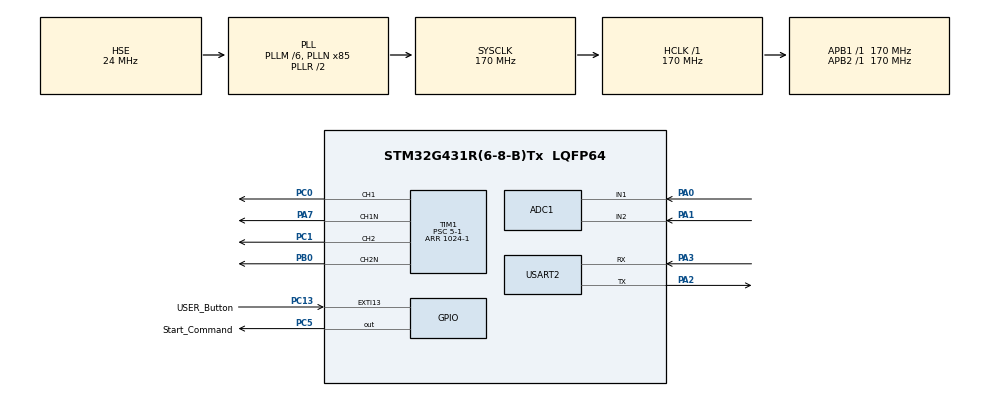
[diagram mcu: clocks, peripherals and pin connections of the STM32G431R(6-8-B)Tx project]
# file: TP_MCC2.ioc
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ADC1.Channel-0\#ChannelRegularConversion=ADC_CHANNEL_1
ADC1.Channel-1\#ChannelRegularConversion=ADC_CHANNEL_2
ADC1.DMAContinuousRequests=ENABLE
ADC1.EOCSelection=ADC_EOC_SEQ_CONV
ADC1.ExternalTrigConv=ADC_EXTERNALTRIG_T1_CC3
ADC1.NbrOfConversion=2
ADC1.NbrOfConversionFlag=1
ADC1.OffsetNumber-0\#ChannelRegularConversion=ADC_OFFSET_NONE
ADC1.OffsetNumber-1\#ChannelRegularConversion=ADC_OFFSET_NONE
ADC1.Rank-0\#ChannelRegularConversion=1
ADC1.Rank-1\#ChannelRegularConversion=2
ADC1.SamplingTime-0\#ChannelRegularConversion=ADC_SAMPLETIME_12CYCLES_5
ADC1.SamplingTime-1\#ChannelRegularConversion=ADC_SAMPLETIME_12CYCLES_5
ADC1.master=1
Dma.ADC1.0.Direction=DMA_PERIPH_TO_MEMORY
Dma.ADC1.0.EventEnable=DISABLE
Dma.ADC1.0.Instance=DMA1_Channel1
Dma.ADC1.0.MemDataAlignment=DMA_MDATAALIGN_HALFWORD
Dma.ADC1.0.MemInc=DMA_MINC_ENABLE
Dma.ADC1.0.Mode=DMA_CIRCULAR
Dma.ADC1.0.PeriphDataAlignment=DMA_PDATAALIGN_HALFWORD
Dma.ADC1.0.PeriphInc=DMA_PINC_DISABLE
Dma.ADC1.0.Polarity=HAL_DMAMUX_REQ_GEN_RISING
Dma.ADC1.0.Priority=DMA_PRIORITY_LOW
Dma.ADC1.0.RequestNumber=1
Dma.ADC1.0.SignalID=NONE
Dma.ADC1.0.SyncEnable=DISABLE
Dma.ADC1.0.SyncPolarity=HAL_DMAMUX_SYNC_NO_EVENT
Dma.ADC1.0.SyncRequestNumber=1
Dma.ADC1.0.SyncSignalID=NONE
Dma.Request0=ADC1
Mcu.Family=STM32G4
Mcu.Name=STM32G431R(6-8-B)Tx
Mcu.Package=LQFP64
NVIC.DMA1_Channel1_IRQn=true\:0\:0\:false\:false\:true\:false\:true
NVIC.EXTI15_10_IRQn=true\:0\:0\:false\:false\:true\:true\:true
NVIC.PriorityGroup=NVIC_PRIORITYGROUP_4
NVIC.TIM6_DAC_IRQn=true\:0\:0\:false\:false\:true\:true\:true
NVIC.USART2_IRQn=true\:0\:0\:false\:false\:true\:true\:true
PA0.Mode=IN1-Single-Ended
PA0.Signal=ADC1_IN1
PA1.Mode=IN2-Single-Ended
PA1.Signal=ADC1_IN2
PA13.Mode=Serial_Wire
PA13.Signal=SYS_JTMS-SWDIO
PA14.Mode=Serial_Wire
PA14.Signal=SYS_JTCK-SWCLK
PA2.Mode=Asynchronous
PA2.Signal=USART2_TX
PA3.Mode=Asynchronous
PA3.Signal=USART2_RX
PA7.Mode=PWM Generation1 CH1 CH1N
PA7.Signal=TIM1_CH1N
PB0.Mode=PWM Generation2 CH2 CH2N
PB0.Signal=TIM1_CH2N
PC0.Signal=S_TIM1_CH1
PC1.Signal=S_TIM1_CH2
PC13.GPIO_Label=USER_Button
PC13.GPIO_ModeDefaultEXTI=GPIO_MODE_IT_FALLING
PC13.Signal=GPXTI13
PC5.GPIO_Label=Start_Command
PC5.Signal=GPIO_Output
PF0-OSC_IN.Mode=HSE-External-Oscillator
PF0-OSC_IN.Signal=RCC_OSC_IN
PF1-OSC_OUT.Mode=HSE-External-Oscillator
PF1-OSC_OUT.Signal=RCC_OSC_OUT
ProjectManager.HeapSize=0x200
ProjectManager.StackSize=0x400
ProjectManager.TargetToolchain=STM32CubeIDE
RCC.ADC12Freq_Value=170000000
RCC.AHBFreq_Value=170000000
RCC.APB1Freq_Value=170000000
RCC.APB1TimFreq_Value=170000000
RCC.APB2Freq_Value=170000000
RCC.APB2TimFreq_Value=170000000
RCC.CortexFreq_Value=170000000
RCC.EXTERNAL_CLOCK_VALUE=12288000
RCC.HCLKFreq_Value=170000000
RCC.HSE_VALUE=24000000
RCC.HSI48_VALUE=48000000
RCC.HSI_VALUE=16000000
RCC.LSE_VALUE=32768
RCC.PLLM=RCC_PLLM_DIV6
RCC.PLLN=85
RCC.PLLSourceVirtual=RCC_PLLSOURCE_HSE
RCC.RTCClockSelection=RCC_RTCCLKSOURCE_LSE
RCC.SYSCLKFreq_VALUE=170000000
RCC.SYSCLKSource=RCC_SYSCLKSOURCE_PLLCLK
RCC.USBFreq_Value=170000000
RCC.VCOOutputFreq_Value=340000000
SH.S_TIM1_CH1.0=TIM1_CH1,PWM Generation1 CH1 CH1N
SH.S_TIM1_CH2.0=TIM1_CH2,PWM Generation2 CH2 CH2N
TIM1.Channel-Output\ Compare3\ No\ Output=TIM_CHANNEL_3
TIM1.Channel-PWM\ Generation1\ CH1\ CH1N=TIM_CHANNEL_1
TIM1.Channel-PWM\ Generation2\ CH2\ CH2N=TIM_CHANNEL_2
TIM1.CounterMode=TIM_COUNTERMODE_CENTERALIGNED1
TIM1.DeadTime=202
TIM1.DeadTimePreload=ENABLE
TIM1.OCMode_3=TIM_OCMODE_PULSE_ON_COMPARE
TIM1.PeriodNoDither=1024-1
TIM1.Prescaler=5-1
TIM1.PulseNoDither_1=533
TIM1.PulseNoDither_2=533
TIM1.TIM_MasterOutputTrigger=TIM_TRGO_OC3REF
TIM6.AutoReloadPreload=TIM_AUTORELOAD_PRELOAD_DISABLE
TIM6.PeriodNoDither=2594-1
TIM6.Prescaler=65536-1
USART2.VirtualMode-Asynchronous=VM_ASYNC
VP_SYS_VS_DBSignals.Mode=DisableDeadBatterySignals
VP_TIM1_VS_ClockSourceINT.Mode=Internal
VP_TIM1_VS_no_output3.Mode=Output Compare3 No Output
VP_TIM6_VS_ClockSourceINT.Mode=Enable_Timer
board=NUCLEO-G431RB

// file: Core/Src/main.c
/* USER CODE BEGIN Header */
/**
  ******************************************************************************
  * @file           : main.c
  * @brief          : Main program body
  ******************************************************************************
  * @attention
  *
  * <h2><center>&copy; Copyright (c) 2021 STMicroelectronics.
  * All rights reserved.</center></h2>
  *
  * This software component is licensed by ST under BSD 3-Clause license,
  * the "License"; You may not use this file except in compliance with the
  * License. You may obtain a copy of the License at:
  *                        opensource.org/licenses/BSD-3-Clause
  *
  ******************************************************************************
  */
/* USER CODE END Header */
#include "main.h"

ADC_HandleTypeDef hadc1;
DMA_HandleTypeDef hdma_adc1;

TIM_HandleTypeDef htim1;
TIM_HandleTypeDef htim6;

UART_HandleTypeDef huart2;

/* USER CODE BEGIN PV */
uint16_t pData[2];// Buffer for the DMA to fill
char uart_rx_buffer[32];// Buffer for the UART to fill

/* USER CODE END PV */

void SystemClock_Config(void);
static void MX_GPIO_Init(void);
static void MX_USART2_UART_Init(void);
static void MX_TIM1_Init(void);
static void MX_DMA_Init(void);
static void MX_ADC1_Init(void);
static void MX_TIM6_Init(void);

int main(void)
{

  /* MCU Configuration--------------------------------------------------------*/

  /* Reset of all peripherals, Initializes the Flash interface and the Systick. */
  HAL_Init();

  /* Configure the system clock */
  SystemClock_Config();

  /* Initialize all configured peripherals */
  MX_GPIO_Init();
  MX_USART2_UART_Init();
  MX_TIM1_Init();
  MX_DMA_Init();
  MX_ADC1_Init();
  MX_TIM6_Init();
  /* USER CODE BEGIN 2 */
  shell_init();// Initialisation of the shell
  HAL_ADCEx_Calibration_Start(&hadc1, ADC_SINGLE_ENDED);// Calibration of the ADC
  HAL_ADC_Start_DMA(&hadc1, (uint32_t*) pData, 2);// Starting the DMA
  HAL_TIM_Base_Start_IT(&htim6);// Starting the Timer 6
  HAL_TIM_Base_Start(&htim1);// Starting the Timer 1

  /* USER CODE END 2 */

  /* Infinite loop */
  /* USER CODE BEGIN WHILE */
  while (1)
  {
	  shellTreatment();
    /* USER CODE END WHILE */

  }
}

void SystemClock_Config(void)
{
  RCC_OscInitTypeDef RCC_OscInitStruct = {0};
  RCC_ClkInitTypeDef RCC_ClkInitStruct = {0};
  RCC_PeriphCLKInitTypeDef PeriphClkInit = {0};

  /** Configure the main internal regulator output voltage
  */
  HAL_PWREx_ControlVoltageScaling(PWR_REGULATOR_VOLTAGE_SCALE1_BOOST);
  /** Initializes the RCC Oscillators according to the specified parameters
  * in the RCC_OscInitTypeDef structure.
  */
  RCC_OscInitStruct.OscillatorType = RCC_OSCILLATORTYPE_HSE;
  RCC_OscInitStruct.HSEState = RCC_HSE_ON;
  RCC_OscInitStruct.PLL.PLLState = RCC_PLL_ON;
  RCC_OscInitStruct.PLL.PLLSource = RCC_PLLSOURCE_HSE;
  RCC_OscInitStruct.PLL.PLLM = RCC_PLLM_DIV6;
  RCC_OscInitStruct.PLL.PLLN = 85;
  RCC_OscInitStruct.PLL.PLLP = RCC_PLLP_DIV2;
  RCC_OscInitStruct.PLL.PLLQ = RCC_PLLQ_DIV2;
  RCC_OscInitStruct.PLL.PLLR = RCC_PLLR_DIV2;
  if (HAL_RCC_OscConfig(&RCC_OscInitStruct) != HAL_OK)
  {
    Error_Handler();
  }
  /** Initializes the CPU, AHB and APB buses clocks
  */
  RCC_ClkInitStruct.ClockType = RCC_CLOCKTYPE_HCLK|RCC_CLOCKTYPE_SYSCLK
                              |RCC_CLOCKTYPE_PCLK1|RCC_CLOCKTYPE_PCLK2;
  RCC_ClkInitStruct.SYSCLKSource = RCC_SYSCLKSOURCE_PLLCLK;
  RCC_ClkInitStruct.AHBCLKDivider = RCC_SYSCLK_DIV1;
  RCC_ClkInitStruct.APB1CLKDivider = RCC_HCLK_DIV1;
  RCC_ClkInitStruct.APB2CLKDivider = RCC_HCLK_DIV1;

  if (HAL_RCC_ClockConfig(&RCC_ClkInitStruct, FLASH_LATENCY_4) != HAL_OK)
  {
    Error_Handler();
  }
  /** Initializes the peripherals clocks
  */
  PeriphClkInit.PeriphClockSelection = RCC_PERIPHCLK_USART2|RCC_PERIPHCLK_ADC12;
  PeriphClkInit.Usart2ClockSelection = RCC_USART2CLKSOURCE_PCLK1;
  PeriphClkInit.Adc12ClockSelection = RCC_ADC12CLKSOURCE_SYSCLK;
  if (HAL_RCCEx_PeriphCLKConfig(&PeriphClkInit) != HAL_OK)
  {
    Error_Handler();
  }
}

static void MX_ADC1_Init(void)
{

  ADC_MultiModeTypeDef multimode = {0};
  ADC_ChannelConfTypeDef sConfig = {0};

  /** Common config
  */
  hadc1.Instance = ADC1;
  hadc1.Init.ClockPrescaler = ADC_CLOCK_SYNC_PCLK_DIV4;
  hadc1.Init.Resolution = ADC_RESOLUTION_12B;
  hadc1.Init.DataAlign = ADC_DATAALIGN_RIGHT;
  hadc1.Init.GainCompensation = 0;
  hadc1.Init.ScanConvMode = ADC_SCAN_DISABLE;
  hadc1.Init.EOCSelection = ADC_EOC_SEQ_CONV;
  hadc1.Init.LowPowerAutoWait = DISABLE;
  hadc1.Init.ContinuousConvMode = DISABLE;
  hadc1.Init.NbrOfConversion = 1;
  hadc1.Init.DiscontinuousConvMode = DISABLE;
  hadc1.Init.ExternalTrigConv = ADC_EXTERNALTRIG_T1_CC3;
  hadc1.Init.ExternalTrigConvEdge = ADC_EXTERNALTRIGCONVEDGE_RISING;
  hadc1.Init.DMAContinuousRequests = ENABLE;
  hadc1.Init.Overrun = ADC_OVR_DATA_PRESERVED;
  hadc1.Init.OversamplingMode = DISABLE;
  if (HAL_ADC_Init(&hadc1) != HAL_OK)
  {
    Error_Handler();
  }
  /** Configure the ADC multi-mode
  */
  multimode.Mode = ADC_MODE_INDEPENDENT;
  if (HAL_ADCEx_MultiModeConfigChannel(&hadc1, &multimode) != HAL_OK)
  {
    Error_Handler();
  }
  /** Configure Regular Channel
  */
  sConfig.Channel = ADC_CHANNEL_1;
  sConfig.Rank = ADC_REGULAR_RANK_1;
  sConfig.SamplingTime = ADC_SAMPLETIME_640CYCLES_5;
  sConfig.SingleDiff = ADC_SINGLE_ENDED;
  sConfig.OffsetNumber = ADC_OFFSET_NONE;
  sConfig.Offset = 0;
  if (HAL_ADC_ConfigChannel(&hadc1, &sConfig) != HAL_OK)
  {
    Error_Handler();
  }

}

static void MX_TIM1_Init(void)
{

  TIM_MasterConfigTypeDef sMasterConfig = {0};
  TIM_OC_InitTypeDef sConfigOC = {0};
  TIM_BreakDeadTimeConfigTypeDef sBreakDeadTimeConfig = {0};

  htim1.Instance = TIM1;
  htim1.Init.Prescaler = 5-1;
  htim1.Init.CounterMode = TIM_COUNTERMODE_CENTERALIGNED1;
  htim1.Init.Period = 1023;
  htim1.Init.ClockDivision = TIM_CLOCKDIVISION_DIV1;
  htim1.Init.RepetitionCounter = 0;
  htim1.Init.AutoReloadPreload = TIM_AUTORELOAD_PRELOAD_DISABLE;
  if (HAL_TIM_PWM_Init(&htim1) != HAL_OK)
  {
    Error_Handler();
  }
  sMasterConfig.MasterOutputTrigger = TIM_TRGO_OC3REF;
  sMasterConfig.MasterOutputTrigger2 = TIM_TRGO2_RESET;
  sMasterConfig.MasterSlaveMode = TIM_MASTERSLAVEMODE_DISABLE;
  if (HAL_TIMEx_MasterConfigSynchronization(&htim1, &sMasterConfig) != HAL_OK)
  {
    Error_Handler();
  }
  sConfigOC.OCMode = TIM_OCMODE_PWM1;
  sConfigOC.Pulse = 533;
  sConfigOC.OCPolarity = TIM_OCPOLARITY_HIGH;
  sConfigOC.OCNPolarity = TIM_OCNPOLARITY_HIGH;
  sConfigOC.OCFastMode = TIM_OCFAST_DISABLE;
  sConfigOC.OCIdleState = TIM_OCIDLESTATE_RESET;
  sConfigOC.OCNIdleState = TIM_OCNIDLESTATE_RESET;
  if (HAL_TIM_PWM_ConfigChannel(&htim1, &sConfigOC, TIM_CHANNEL_1) != HAL_OK)
  {
    Error_Handler();
  }
  if (HAL_TIM_PWM_ConfigChannel(&htim1, &sConfigOC, TIM_CHANNEL_2) != HAL_OK)
  {
    Error_Handler();
  }
  HAL_TIMEx_EnableDeadTimePreload(&htim1);
  sBreakDeadTimeConfig.OffStateRunMode = TIM_OSSR_DISABLE;
  sBreakDeadTimeConfig.OffStateIDLEMode = TIM_OSSI_DISABLE;
  sBreakDeadTimeConfig.LockLevel = TIM_LOCKLEVEL_OFF;
  sBreakDeadTimeConfig.DeadTime = 202;
  sBreakDeadTimeConfig.BreakState = TIM_BREAK_DISABLE;
  sBreakDeadTimeConfig.BreakPolarity = TIM_BREAKPOLARITY_HIGH;
  sBreakDeadTimeConfig.BreakFilter = 0;
  sBreakDeadTimeConfig.BreakAFMode = TIM_BREAK_AFMODE_INPUT;
  sBreakDeadTimeConfig.Break2State = TIM_BREAK2_DISABLE;
  sBreakDeadTimeConfig.Break2Polarity = TIM_BREAK2POLARITY_HIGH;
  sBreakDeadTimeConfig.Break2Filter = 0;
  sBreakDeadTimeConfig.Break2AFMode = TIM_BREAK_AFMODE_INPUT;
  sBreakDeadTimeConfig.AutomaticOutput = TIM_AUTOMATICOUTPUT_DISABLE;
  if (HAL_TIMEx_ConfigBreakDeadTime(&htim1, &sBreakDeadTimeConfig) != HAL_OK)
  {
    Error_Handler();
  }
  HAL_TIM_MspPostInit(&htim1);

}

static void MX_TIM6_Init(void)
{

  TIM_MasterConfigTypeDef sMasterConfig = {0};

  htim6.Instance = TIM6;
  htim6.Init.Prescaler = 65536-1;
  htim6.Init.CounterMode = TIM_COUNTERMODE_UP;
  htim6.Init.Period = 2593;
  htim6.Init.AutoReloadPreload = TIM_AUTORELOAD_PRELOAD_DISABLE;
  if (HAL_TIM_Base_Init(&htim6) != HAL_OK)
  {
    Error_Handler();
  }
  sMasterConfig.MasterOutputTrigger = TIM_TRGO_RESET;
  sMasterConfig.MasterSlaveMode = TIM_MASTERSLAVEMODE_DISABLE;
  if (HAL_TIMEx_MasterConfigSynchronization(&htim6, &sMasterConfig) != HAL_OK)
  {
    Error_Handler();
  }

}

static void MX_USART2_UART_Init(void)
{

  huart2.Instance = USART2;
  huart2.Init.BaudRate = 115200;
  huart2.Init.WordLength = UART_WORDLENGTH_8B;
  huart2.Init.StopBits = UART_STOPBITS_1;
  huart2.Init.Parity = UART_PARITY_NONE;
  huart2.Init.Mode = UART_MODE_TX_RX;
  huart2.Init.HwFlowCtl = UART_HWCONTROL_NONE;
  huart2.Init.OverSampling = UART_OVERSAMPLING_16;
  huart2.Init.OneBitSampling = UART_ONE_BIT_SAMPLE_DISABLE;
  huart2.Init.ClockPrescaler = UART_PRESCALER_DIV1;
  huart2.AdvancedInit.AdvFeatureInit = UART_ADVFEATURE_NO_INIT;
  if (HAL_UART_Init(&huart2) != HAL_OK)
  {
    Error_Handler();
  }
  if (HAL_UARTEx_SetTxFifoThreshold(&huart2, UART_TXFIFO_THRESHOLD_1_8) != HAL_OK)
  {
    Error_Handler();
  }
  if (HAL_UARTEx_SetRxFifoThreshold(&huart2, UART_RXFIFO_THRESHOLD_1_8) != HAL_OK)
  {
    Error_Handler();
  }
  if (HAL_UARTEx_DisableFifoMode(&huart2) != HAL_OK)
  {
    Error_Handler();
  }

}

static void MX_DMA_Init(void)
{

  /* DMA controller clock enable */
  __HAL_RCC_DMAMUX1_CLK_ENABLE();
  __HAL_RCC_DMA1_CLK_ENABLE();

  /* DMA interrupt init */
  /* DMA1_Channel1_IRQn interrupt configuration */
  HAL_NVIC_SetPriority(DMA1_Channel1_IRQn, 0, 0);
  HAL_NVIC_EnableIRQ(DMA1_Channel1_IRQn);

}

static void MX_GPIO_Init(void)
{
  GPIO_InitTypeDef GPIO_InitStruct = {0};

  /* GPIO Ports Clock Enable */
  __HAL_RCC_GPIOC_CLK_ENABLE();
  __HAL_RCC_GPIOF_CLK_ENABLE();
  __HAL_RCC_GPIOA_CLK_ENABLE();
  __HAL_RCC_GPIOB_CLK_ENABLE();

  /*Configure GPIO pin Output Level */
  HAL_GPIO_WritePin(Start_Command_GPIO_Port, Start_Command_Pin, GPIO_PIN_RESET);

  /*Configure GPIO pin : USER_Button_Pin */
  GPIO_InitStruct.Pin = USER_Button_Pin;
  GPIO_InitStruct.Mode = GPIO_MODE_IT_FALLING;
  GPIO_InitStruct.Pull = GPIO_NOPULL;
  HAL_GPIO_Init(USER_Button_GPIO_Port, &GPIO_InitStruct);

  /*Configure GPIO pin : Start_Command_Pin */
  GPIO_InitStruct.Pin = Start_Command_Pin;
  GPIO_InitStruct.Mode = GPIO_MODE_OUTPUT_PP;
  GPIO_InitStruct.Pull = GPIO_NOPULL;
  GPIO_InitStruct.Speed = GPIO_SPEED_FREQ_LOW;
  HAL_GPIO_Init(Start_Command_GPIO_Port, &GPIO_InitStruct);

  /* EXTI interrupt init*/
  HAL_NVIC_SetPriority(EXTI15_10_IRQn, 0, 0);
  HAL_NVIC_EnableIRQ(EXTI15_10_IRQn);

}

/* USER CODE BEGIN 4 */

void HAL_TIM_PeriodElapsedCallback(TIM_HandleTypeDef *htim){
	if (htim == &htim6){
		sprintf(uart_rx_buffer,"ADC 1 = %4d -- ADC 2 = %4d \r\n",pData[0],pData[1]);
		//uart_write(pData[0], 1);
		HAL_UART_Transmit(&huart2, (uint16_t*)uart_rx_buffer, 32, HAL_MAX_DELAY);
	}
}

void HAL_ADC_ConvCpltCallback(ADC_HandleTypeDef *hadc){
	uart_write("Issou\r\n", 7);
}

/* USER CODE END 4 */

void Error_Handler(void)
{
  __disable_irq();
  while (1)
  {
  }
}

/************************ (C) COPYRIGHT STMicroelectronics *****END OF FILE****/
